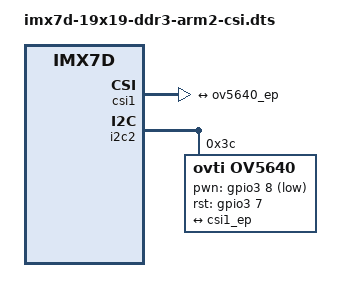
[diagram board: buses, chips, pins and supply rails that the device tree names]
/*
 * Copyright (C) 2015 Freescale Semiconductor, Inc.
 *
 * This program is free software; you can redistribute it and/or modify
 * it under the terms of the GNU General Public License version 2 as
 * published by the Free Software Foundation.
 */

#include "imx7d-19x19-ddr3-arm2.dts"

&csi1 {
	status = "okay";

	port {
		csi1_ep: endpoint {
			remote-endpoint = <&ov5640_ep>;
		};
	};
};

&i2c2 {
	ov5640: ov5640@3c {
		compatible = "ovti,ov5640";
		reg = <0x3c>;
		pinctrl-names = "default";
		pinctrl-0 = <&pinctrl_csi>;
		clocks = <&clks IMX7D_CSI_MCLK_ROOT_CLK>;
		clock-names = "csi_mclk";
		pwn-gpios = <&gpio3 8 1>;
		rst-gpios = <&gpio3 7 0>;
		csi_id = <0>;
		mclk = <24000000>;
		mclk_source = <0>;
		status = "okay";
		port {
			ov5640_ep: endpoint {
				remote-endpoint = <&csi1_ep>;
			};
		};
	};
};

&lcdif {
	status = "disabled";
};

